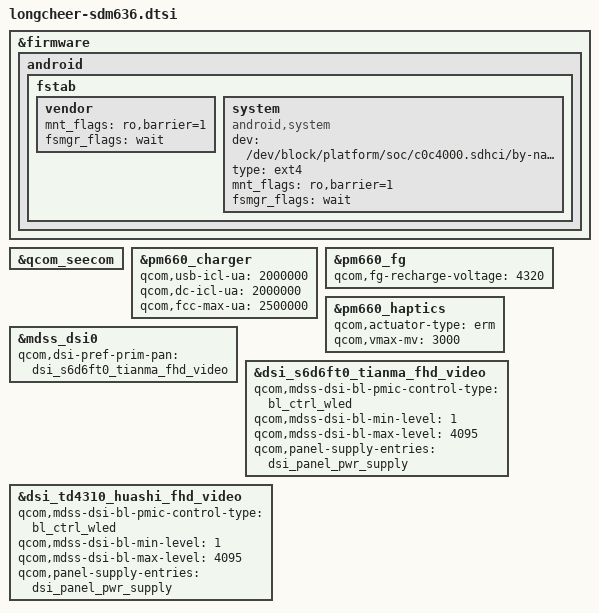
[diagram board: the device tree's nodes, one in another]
/* Copyright (c) 2019, The Linux Foundation. All rights reserved.
 *
 * This program is free software; you can redistribute it and/or modify
 * it under the terms of the GNU General Public License version 2 and
 * only version 2 as published by the Free Software Foundation.
 *
 * This program is distributed in the hope that it will be useful,
 * but WITHOUT ANY WARRANTY; without even the implied warranty of
 * MERCHANTABILITY or FITNESS FOR A PARTICULAR PURPOSE.  See the
 * GNU General Public License for more details.
 */

/* sdm660.dtsi m1851 specific diff */
&firmware {
	android {
		fstab {
			vendor {
				mnt_flags = "ro,barrier=1";
				fsmgr_flags = "wait";
			};

			system {
				compatible = "android,system";
				dev = "/dev/block/platform/soc/c0c4000.sdhci/by-name/system";
				type = "ext4";
				mnt_flags = "ro,barrier=1";
				fsmgr_flags = "wait";
				status = "ok";
			};
		};
	};
};

&qcom_seecom {
	/delete-property/ qcom,fde-key-size;
};


/* msm-pm660.dtsi m1851 specific diff */
&pm660_charger {
	qcom,usb-icl-ua = <2000000>;
	qcom,dc-icl-ua = <2000000>;
	qcom,fcc-max-ua = <2500000>;
};

&pm660_fg {
	qcom,fg-recharge-voltage = <4320>;
};

&pm660_haptics {
	qcom,actuator-type = "erm";
	qcom,vmax-mv = <3000>;
};

/* sdm636-mtp.dtsi diff */
&mdss_dsi0 {
	qcom,dsi-pref-prim-pan = <&dsi_s6d6ft0_tianma_fhd_video>;
};

&dsi_s6d6ft0_tianma_fhd_video {
	qcom,mdss-dsi-bl-pmic-control-type = "bl_ctrl_wled";
	qcom,mdss-dsi-bl-min-level = <1>;
	qcom,mdss-dsi-bl-max-level = <4095>;
	qcom,panel-supply-entries = <&dsi_panel_pwr_supply>;
};

&dsi_td4310_huashi_fhd_video {
	qcom,mdss-dsi-bl-pmic-control-type = "bl_ctrl_wled";
	qcom,mdss-dsi-bl-min-level = <1>;
	qcom,mdss-dsi-bl-max-level = <4095>;
	qcom,panel-supply-entries = <&dsi_panel_pwr_supply>;
};
